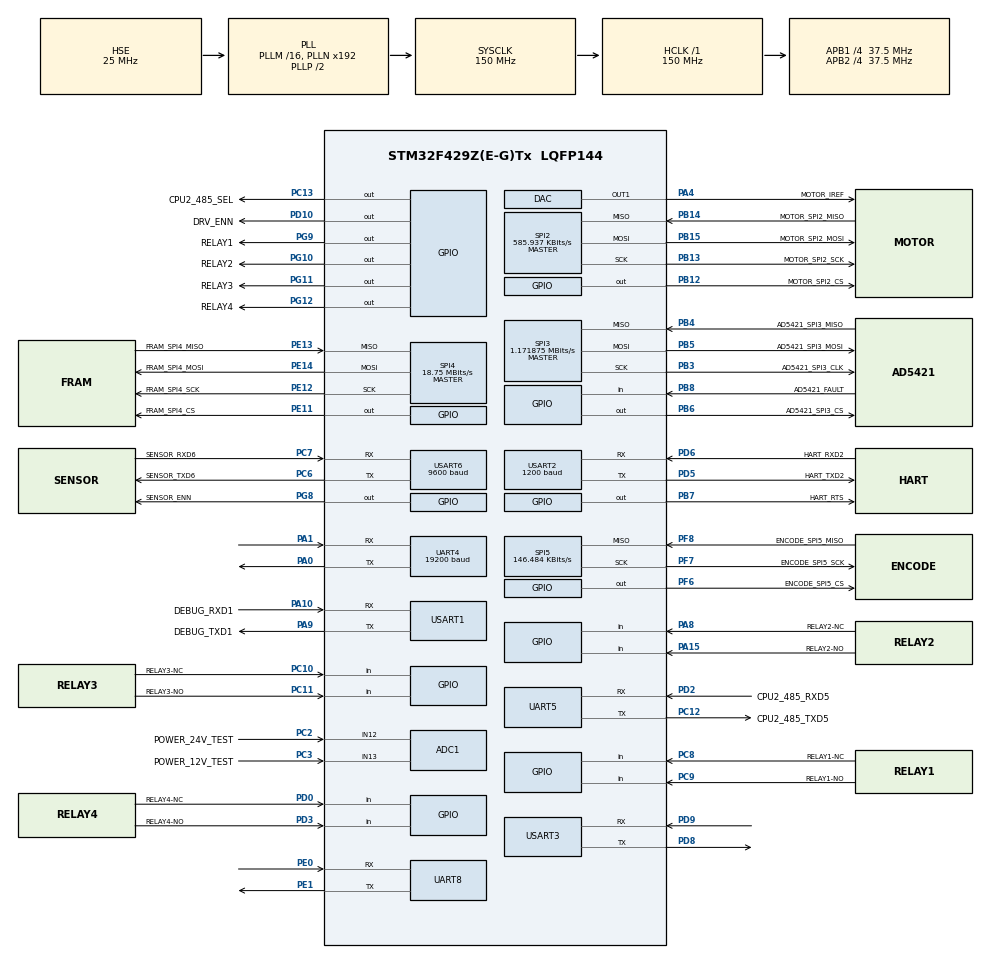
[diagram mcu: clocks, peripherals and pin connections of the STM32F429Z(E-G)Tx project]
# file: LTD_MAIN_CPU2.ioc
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ADC1.Channel-0\#ChannelRegularConversion=ADC_CHANNEL_12
ADC1.ClockPrescaler=ADC_CLOCK_SYNC_PCLK_DIV4
ADC1.ContinuousConvMode=ENABLE
ADC1.DMAContinuousRequests=ENABLE
ADC1.NbrOfConversionFlag=1
ADC1.Rank-0\#ChannelRegularConversion=1
ADC1.SamplingTime-0\#ChannelRegularConversion=ADC_SAMPLETIME_144CYCLES
ADC1.master=1
Dma.Request0=UART4_RX
Dma.Request1=SPI5_RX
Dma.Request2=USART1_RX
Dma.Request3=USART2_RX
Dma.Request4=UART5_RX
Dma.Request5=UART5_TX
Dma.Request6=USART2_TX
Dma.Request7=USART6_TX
Dma.Request8=USART6_RX
Dma.Request9=ADC1
Dma.ADC1.9.Direction=DMA_PERIPH_TO_MEMORY
Dma.ADC1.9.FIFOMode=DMA_FIFOMODE_DISABLE
Dma.ADC1.9.Instance=DMA2_Stream0
Dma.ADC1.9.MemDataAlignment=DMA_MDATAALIGN_WORD
Dma.ADC1.9.MemInc=DMA_MINC_DISABLE
Dma.ADC1.9.Mode=DMA_CIRCULAR
Dma.ADC1.9.PeriphDataAlignment=DMA_PDATAALIGN_WORD
Dma.ADC1.9.PeriphInc=DMA_PINC_DISABLE
Dma.ADC1.9.Priority=DMA_PRIORITY_LOW
Dma.SPI5_RX.1.Direction=DMA_PERIPH_TO_MEMORY
Dma.SPI5_RX.1.FIFOMode=DMA_FIFOMODE_DISABLE
Dma.SPI5_RX.1.Instance=DMA2_Stream3
Dma.SPI5_RX.1.MemDataAlignment=DMA_MDATAALIGN_BYTE
Dma.SPI5_RX.1.MemInc=DMA_MINC_ENABLE
Dma.SPI5_RX.1.Mode=DMA_NORMAL
Dma.SPI5_RX.1.PeriphDataAlignment=DMA_PDATAALIGN_BYTE
Dma.SPI5_RX.1.PeriphInc=DMA_PINC_DISABLE
Dma.SPI5_RX.1.Priority=DMA_PRIORITY_LOW
Dma.UART4_RX.0.Direction=DMA_PERIPH_TO_MEMORY
Dma.UART4_RX.0.FIFOMode=DMA_FIFOMODE_DISABLE
Dma.UART4_RX.0.Instance=DMA1_Stream2
Dma.UART4_RX.0.MemDataAlignment=DMA_MDATAALIGN_BYTE
Dma.UART4_RX.0.MemInc=DMA_MINC_ENABLE
Dma.UART4_RX.0.Mode=DMA_NORMAL
Dma.UART4_RX.0.PeriphDataAlignment=DMA_PDATAALIGN_BYTE
Dma.UART4_RX.0.PeriphInc=DMA_PINC_DISABLE
Dma.UART4_RX.0.Priority=DMA_PRIORITY_LOW
Dma.UART5_RX.4.Direction=DMA_PERIPH_TO_MEMORY
Dma.UART5_RX.4.FIFOMode=DMA_FIFOMODE_DISABLE
Dma.UART5_RX.4.Instance=DMA1_Stream0
Dma.UART5_RX.4.MemDataAlignment=DMA_MDATAALIGN_BYTE
Dma.UART5_RX.4.MemInc=DMA_MINC_ENABLE
Dma.UART5_RX.4.Mode=DMA_NORMAL
Dma.UART5_RX.4.PeriphDataAlignment=DMA_PDATAALIGN_BYTE
Dma.UART5_RX.4.PeriphInc=DMA_PINC_DISABLE
Dma.UART5_RX.4.Priority=DMA_PRIORITY_LOW
Dma.UART5_TX.5.Direction=DMA_MEMORY_TO_PERIPH
Dma.UART5_TX.5.FIFOMode=DMA_FIFOMODE_DISABLE
Dma.UART5_TX.5.Instance=DMA1_Stream7
Dma.UART5_TX.5.MemDataAlignment=DMA_MDATAALIGN_BYTE
Dma.UART5_TX.5.MemInc=DMA_MINC_ENABLE
Dma.UART5_TX.5.Mode=DMA_NORMAL
Dma.UART5_TX.5.PeriphDataAlignment=DMA_PDATAALIGN_BYTE
Dma.UART5_TX.5.PeriphInc=DMA_PINC_DISABLE
Dma.UART5_TX.5.Priority=DMA_PRIORITY_LOW
Dma.USART1_RX.2.Direction=DMA_PERIPH_TO_MEMORY
Dma.USART1_RX.2.FIFOMode=DMA_FIFOMODE_DISABLE
Dma.USART1_RX.2.Instance=DMA2_Stream2
Dma.USART1_RX.2.MemDataAlignment=DMA_MDATAALIGN_BYTE
Dma.USART1_RX.2.MemInc=DMA_MINC_ENABLE
Dma.USART1_RX.2.Mode=DMA_NORMAL
Dma.USART1_RX.2.PeriphDataAlignment=DMA_PDATAALIGN_BYTE
Dma.USART1_RX.2.PeriphInc=DMA_PINC_DISABLE
Dma.USART1_RX.2.Priority=DMA_PRIORITY_LOW
Dma.USART2_RX.3.Direction=DMA_PERIPH_TO_MEMORY
Dma.USART2_RX.3.FIFOMode=DMA_FIFOMODE_DISABLE
Dma.USART2_RX.3.Instance=DMA1_Stream5
Dma.USART2_RX.3.MemDataAlignment=DMA_MDATAALIGN_BYTE
Dma.USART2_RX.3.MemInc=DMA_MINC_ENABLE
Dma.USART2_RX.3.Mode=DMA_NORMAL
Dma.USART2_RX.3.PeriphDataAlignment=DMA_PDATAALIGN_BYTE
Dma.USART2_RX.3.PeriphInc=DMA_PINC_DISABLE
Dma.USART2_RX.3.Priority=DMA_PRIORITY_LOW
Dma.USART2_TX.6.Direction=DMA_MEMORY_TO_PERIPH
Dma.USART2_TX.6.FIFOMode=DMA_FIFOMODE_DISABLE
Dma.USART2_TX.6.Instance=DMA1_Stream6
Dma.USART2_TX.6.MemDataAlignment=DMA_MDATAALIGN_BYTE
Dma.USART2_TX.6.MemInc=DMA_MINC_ENABLE
Dma.USART2_TX.6.Mode=DMA_NORMAL
Dma.USART2_TX.6.PeriphDataAlignment=DMA_PDATAALIGN_BYTE
Dma.USART2_TX.6.PeriphInc=DMA_PINC_DISABLE
Dma.USART2_TX.6.Priority=DMA_PRIORITY_LOW
Dma.USART6_RX.8.Direction=DMA_PERIPH_TO_MEMORY
Dma.USART6_RX.8.FIFOMode=DMA_FIFOMODE_DISABLE
Dma.USART6_RX.8.Instance=DMA2_Stream1
Dma.USART6_RX.8.MemDataAlignment=DMA_MDATAALIGN_BYTE
Dma.USART6_RX.8.MemInc=DMA_MINC_ENABLE
Dma.USART6_RX.8.Mode=DMA_NORMAL
Dma.USART6_RX.8.PeriphDataAlignment=DMA_PDATAALIGN_BYTE
Dma.USART6_RX.8.PeriphInc=DMA_PINC_DISABLE
Dma.USART6_RX.8.Priority=DMA_PRIORITY_LOW
Dma.USART6_TX.7.Direction=DMA_MEMORY_TO_PERIPH
Dma.USART6_TX.7.FIFOMode=DMA_FIFOMODE_DISABLE
Dma.USART6_TX.7.Instance=DMA2_Stream6
Dma.USART6_TX.7.MemDataAlignment=DMA_MDATAALIGN_BYTE
Dma.USART6_TX.7.MemInc=DMA_MINC_ENABLE
Dma.USART6_TX.7.Mode=DMA_NORMAL
Dma.USART6_TX.7.PeriphDataAlignment=DMA_PDATAALIGN_BYTE
Dma.USART6_TX.7.PeriphInc=DMA_PINC_DISABLE
Dma.USART6_TX.7.Priority=DMA_PRIORITY_LOW
IWDG.Prescaler=IWDG_PRESCALER_32
Mcu.Family=STM32F4
Mcu.Name=STM32F429Z(E-G)Tx
Mcu.Package=LQFP144
NVIC.ADC_IRQn=true\:1\:0\:false\:false\:true\:true\:true\:true
NVIC.DMA1_Stream0_IRQn=true\:2\:0\:false\:false\:true\:false\:true\:true
NVIC.DMA1_Stream2_IRQn=true\:3\:0\:false\:false\:true\:false\:true\:true
NVIC.DMA1_Stream5_IRQn=true\:4\:0\:false\:false\:true\:false\:true\:true
NVIC.DMA1_Stream6_IRQn=true\:4\:0\:false\:false\:true\:false\:true\:true
NVIC.DMA1_Stream7_IRQn=true\:2\:0\:false\:false\:true\:false\:true\:true
NVIC.DMA2_Stream1_IRQn=true\:1\:0\:false\:false\:true\:false\:true\:true
NVIC.DMA2_Stream2_IRQn=true\:4\:0\:false\:false\:true\:false\:true\:true
NVIC.DMA2_Stream3_IRQn=true\:0\:0\:false\:false\:true\:false\:true\:true
NVIC.DMA2_Stream6_IRQn=true\:1\:0\:false\:false\:true\:false\:true\:true
NVIC.PriorityGroup=NVIC_PRIORITYGROUP_4
NVIC.TIM1_UP_TIM10_IRQn=true\:0\:0\:true\:false\:true\:true\:true\:true
NVIC.TIM4_IRQn=true\:3\:0\:false\:false\:true\:true\:true\:true
NVIC.UART4_IRQn=true\:2\:0\:true\:false\:true\:true\:true\:true
NVIC.UART5_IRQn=true\:2\:0\:true\:false\:true\:true\:true\:true
NVIC.USART1_IRQn=true\:4\:0\:false\:false\:true\:true\:true\:true
NVIC.USART2_IRQn=true\:4\:0\:false\:false\:true\:true\:true\:true
NVIC.USART6_IRQn=true\:1\:0\:false\:false\:true\:true\:true\:true
PA0/WKUP.Mode=Asynchronous
PA0/WKUP.Signal=UART4_TX
PA1.Mode=Asynchronous
PA1.Signal=UART4_RX
PA10.GPIO_Label=DEBUG_RXD1
PA10.GPIO_PuPd=GPIO_PULLUP
PA10.Mode=Asynchronous
PA10.Signal=USART1_RX
PA13.Mode=Serial_Wire
PA13.Signal=SYS_JTMS-SWDIO
PA14.Mode=Serial_Wire
PA14.Signal=SYS_JTCK-SWCLK
PA15.GPIO_Label=RELAY2-NO
PA15.Signal=GPIO_Input
PA4.GPIO_Label=MOTOR_IREF
PA4.Signal=COMP_DAC1_group
PA8.GPIO_Label=RELAY2-NC
PA8.Signal=GPIO_Input
PA9.GPIO_Label=DEBUG_TXD1
PA9.Mode=Asynchronous
PA9.Signal=USART1_TX
PB12.GPIO_Label=MOTOR_SPI2_CS
PB12.PinState=GPIO_PIN_SET
PB12.Signal=GPIO_Output
PB13.GPIO_Label=MOTOR_SPI2_SCK
PB13.Mode=Full_Duplex_Master
PB13.Signal=SPI2_SCK
PB14.GPIO_Label=MOTOR_SPI2_MISO
PB14.Mode=Full_Duplex_Master
PB14.Signal=SPI2_MISO
PB15.GPIO_Label=MOTOR_SPI2_MOSI
PB15.Mode=Full_Duplex_Master
PB15.Signal=SPI2_MOSI
PB3.GPIO_Label=AD5421_SPI3_CLK
PB3.Mode=Full_Duplex_Master
PB3.Signal=SPI3_SCK
PB4.GPIO_Label=AD5421_SPI3_MISO
PB4.Mode=Full_Duplex_Master
PB4.Signal=SPI3_MISO
PB5.GPIO_Label=AD5421_SPI3_MOSI
PB5.Mode=Full_Duplex_Master
PB5.Signal=SPI3_MOSI
PB6.GPIO_Label=AD5421_SPI3_CS
PB6.Signal=GPIO_Output
PB7.GPIO_Label=HART_RTS
PB7.Signal=GPIO_Output
PB8.GPIO_Label=AD5421_FAULT
PB8.Signal=GPIO_Input
PC10.GPIO_Label=RELAY3-NC
PC10.Signal=GPIO_Input
PC11.GPIO_Label=RELAY3-NO
PC11.Signal=GPIO_Input
PC12.GPIO_Label=CPU2_485_TXD5
PC12.Mode=Asynchronous
PC12.Signal=UART5_TX
PC13.GPIO_Label=CPU2_485_SEL
PC13.PinState=GPIO_PIN_SET
PC13.Signal=GPIO_Output
PC2.GPIO_Label=POWER_24V_TEST
PC2.Signal=ADCx_IN12
PC3.GPIO_Label=POWER_12V_TEST
PC3.Signal=ADCx_IN13
PC6.GPIO_Label=SENSOR_TXD6
PC6.Mode=Asynchronous
PC6.Signal=USART6_TX
PC7.GPIO_Label=SENSOR_RXD6
PC7.Mode=Asynchronous
PC7.Signal=USART6_RX
PC8.GPIO_Label=RELAY1-NC
PC8.Signal=GPIO_Input
PC9.GPIO_Label=RELAY1-NO
PC9.Signal=GPIO_Input
PD0.GPIO_Label=RELAY4-NC
PD0.Signal=GPIO_Input
PD10.GPIO_Label=DRV_ENN
PD10.PinState=GPIO_PIN_SET
PD10.Signal=GPIO_Output
PD2.GPIO_Label=CPU2_485_RXD5
PD2.Mode=Asynchronous
PD2.Signal=UART5_RX
PD3.GPIO_Label=RELAY4-NO
PD3.Signal=GPIO_Input
PD5.GPIO_Label=HART_TXD2
PD5.Mode=Asynchronous
PD5.Signal=USART2_TX
PD6.GPIO_Label=HART_RXD2
PD6.Mode=Asynchronous
PD6.Signal=USART2_RX
PD8.Mode=Asynchronous
PD8.Signal=USART3_TX
PD9.Mode=Asynchronous
PD9.Signal=USART3_RX
PE0.Mode=Asynchronous
PE0.Signal=UART8_RX
PE1.Mode=Asynchronous
PE1.Signal=UART8_TX
PE11.GPIO_Label=FRAM_SPI4_CS
PE11.PinState=GPIO_PIN_SET
PE11.Signal=GPIO_Output
PE12.GPIO_Label=FRAM_SPI4_SCK
PE12.Mode=Full_Duplex_Master
PE12.Signal=SPI4_SCK
PE13.GPIO_Label=FRAM_SPI4_MISO
PE13.Mode=Full_Duplex_Master
PE13.Signal=SPI4_MISO
PE14.GPIO_Label=FRAM_SPI4_MOSI
PE14.Mode=Full_Duplex_Master
PE14.Signal=SPI4_MOSI
PF6.GPIO_Label=ENCODE_SPI5_CS
PF6.PinState=GPIO_PIN_SET
PF6.Signal=GPIO_Output
PF7.GPIO_Label=ENCODE_SPI5_SCK
PF7.Mode=RX_Only_Simplex_Unidirect_Master
PF7.Signal=SPI5_SCK
PF8.GPIO_Label=ENCODE_SPI5_MISO
PF8.GPIO_PuPd=GPIO_PULLDOWN
PF8.Mode=RX_Only_Simplex_Unidirect_Master
PF8.Signal=SPI5_MISO
PG10.GPIO_Label=RELAY2
PG10.Signal=GPIO_Output
PG11.GPIO_Label=RELAY3
PG11.Signal=GPIO_Output
PG12.GPIO_Label=RELAY4
PG12.Signal=GPIO_Output
PG8.GPIO_Label=SENSOR_ENN
PG8.PinState=GPIO_PIN_SET
PG8.Signal=GPIO_Output
PG9.GPIO_Label=RELAY1
PG9.Signal=GPIO_Output
PH0/OSC_IN.Mode=HSE-External-Oscillator
PH0/OSC_IN.Signal=RCC_OSC_IN
PH1/OSC_OUT.Mode=HSE-External-Oscillator
PH1/OSC_OUT.Signal=RCC_OSC_OUT
ProjectManager.HeapSize=0x200
ProjectManager.StackSize=0x400
ProjectManager.TargetToolchain=STM32CubeIDE
RCC.48MHZClocksFreq_Value=75000000
RCC.AHBFreq_Value=150000000
RCC.APB1CLKDivider=RCC_HCLK_DIV4
RCC.APB1Freq_Value=37500000
RCC.APB1TimFreq_Value=75000000
RCC.APB2CLKDivider=RCC_HCLK_DIV4
RCC.APB2Freq_Value=37500000
RCC.APB2TimFreq_Value=75000000
RCC.CortexFreq_Value=150000000
RCC.HCLKFreq_Value=150000000
RCC.HSE_VALUE=25000000
RCC.HSI_VALUE=16000000
RCC.LSE_VALUE=32768
RCC.PLLSourceVirtual=RCC_PLLSOURCE_HSE
RCC.SYSCLKFreq_VALUE=150000000
RCC.SYSCLKSource=RCC_SYSCLKSOURCE_PLLCLK
RCC.VCOOutputFreq_Value=300000000
SH.ADCx_IN12.0=ADC1_IN12,IN12
SH.ADCx_IN13.0=ADC1_IN13,IN13
SH.COMP_DAC1_group.0=DAC_OUT1,DAC_OUT1
SPI2.BaudRatePrescaler=SPI_BAUDRATEPRESCALER_64
SPI2.CLKPhase=SPI_PHASE_2EDGE
SPI2.CLKPolarity=SPI_POLARITY_HIGH
SPI2.CalculateBaudRate=585.937 KBits/s
SPI2.Direction=SPI_DIRECTION_2LINES
SPI2.Mode=SPI_MODE_MASTER
SPI2.VirtualType=VM_MASTER
SPI3.BaudRatePrescaler=SPI_BAUDRATEPRESCALER_32
SPI3.CLKPhase=SPI_PHASE_2EDGE
SPI3.CalculateBaudRate=1.171875 MBits/s
SPI3.Direction=SPI_DIRECTION_2LINES
SPI3.Mode=SPI_MODE_MASTER
SPI3.VirtualType=VM_MASTER
SPI4.BaudRatePrescaler=SPI_BAUDRATEPRESCALER_2
SPI4.CalculateBaudRate=18.75 MBits/s
SPI4.Direction=SPI_DIRECTION_2LINES
SPI4.Mode=SPI_MODE_MASTER
SPI4.VirtualType=VM_MASTER
SPI5.BaudRatePrescaler=SPI_BAUDRATEPRESCALER_256
SPI5.CLKPhase=SPI_PHASE_2EDGE
SPI5.CLKPolarity=SPI_POLARITY_HIGH
SPI5.CalculateBaudRate=146.484 KBits/s
SPI5.Direction=SPI_DIRECTION_2LINES_RXONLY
SPI5.Mode=SPI_MODE_MASTER
SPI5.VirtualType=VM_MASTER
TIM1.Period=99
TIM1.Prescaler=7499
TIM4.AutoReloadPreload=TIM_AUTORELOAD_PRELOAD_ENABLE
TIM4.Period=1249
TIM4.Prescaler=14999
UART4.BaudRate=19200
UART4.VirtualMode=Asynchronous
UART5.VirtualMode=Asynchronous
UART8.VirtualMode=Asynchronous
USART1.VirtualMode=VM_ASYNC
USART2.BaudRate=1200
USART2.Parity=PARITY_NONE
USART2.VirtualMode=VM_ASYNC
USART2.WordLength=WORDLENGTH_9B
USART3.VirtualMode=VM_ASYNC
USART6.BaudRate=9600
USART6.VirtualMode=VM_ASYNC
VP_CRC_VS_CRC.Mode=CRC_Activate
VP_IWDG_VS_IWDG.Mode=IWDG_Activate
VP_TIM1_VS_ClockSourceINT.Mode=Internal
VP_TIM4_VS_ClockSourceINT.Mode=Internal
board=custom

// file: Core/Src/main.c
/* USER CODE BEGIN Header */
/**
 ******************************************************************************
 * @file           : main.c
 * @brief          : Main program body
 ******************************************************************************
 * @attention
 *
 * Copyright (c) 2025 STMicroelectronics.
 * All rights reserved.
 *
 * This software is licensed under terms that can be found in the LICENSE file
 * in the root directory of this software component.
 * If no LICENSE file comes with this software, it is provided AS-IS.
 *
 ******************************************************************************
 */
/* USER CODE END Header */
#include "main.h"
#include "adc.h"
#include "crc.h"
#include "dac.h"
#include "dma.h"
#include "iwdg.h"
#include "spi.h"
#include "tim.h"
#include "usart.h"
#include "gpio.h"

/* USER CODE BEGIN Includes */
#include "app_main.h"
#include "motor_ctrl.h"
/* USER CODE END Includes */

void SystemClock_Config(void);

int main(void)
{

  /* MCU Configuration--------------------------------------------------------*/

  /* Reset of all peripherals, Initializes the Flash interface and the Systick. */
  HAL_Init();

  /* Configure the system clock */
  SystemClock_Config();

  /* Initialize all configured peripherals */
  MX_GPIO_Init();
  MX_DMA_Init();
  MX_ADC1_Init();
  MX_DAC_Init();
  MX_UART4_Init();
  MX_UART5_Init();
  MX_UART8_Init();
  MX_USART1_UART_Init();
  MX_USART6_UART_Init();
  MX_SPI3_Init();
  MX_SPI2_Init();
  MX_SPI4_Init();
  MX_SPI5_Init();
  MX_USART2_UART_Init();
  MX_USART3_UART_Init();
  MX_TIM1_Init();
  MX_CRC_Init();
  MX_IWDG_Init();
  MX_TIM4_Init();
  /* USER CODE BEGIN 2 */
	/* 业务初始化前先清 TMC5130 残留运动状态，避免运动中复位后继续跑。 */
	(void)MotorCtrl_BootSafeStop();
	App_Init();
  /* USER CODE END 2 */

  /* Infinite loop */
	while (1) {

    /* USER CODE BEGIN 3 */
		App_MainLoop();
	}
  /* USER CODE END 3 */
}

void SystemClock_Config(void)
{
  RCC_OscInitTypeDef RCC_OscInitStruct = {0};
  RCC_ClkInitTypeDef RCC_ClkInitStruct = {0};

  /** Configure the main internal regulator output voltage
  */
  __HAL_RCC_PWR_CLK_ENABLE();
  __HAL_PWR_VOLTAGESCALING_CONFIG(PWR_REGULATOR_VOLTAGE_SCALE1);

  /** Initializes the RCC Oscillators according to the specified parameters
  * in the RCC_OscInitTypeDef structure.
  */
  RCC_OscInitStruct.OscillatorType = RCC_OSCILLATORTYPE_LSI|RCC_OSCILLATORTYPE_HSE;
  RCC_OscInitStruct.HSEState = RCC_HSE_ON;
  RCC_OscInitStruct.LSIState = RCC_LSI_ON;
  RCC_OscInitStruct.PLL.PLLState = RCC_PLL_ON;
  RCC_OscInitStruct.PLL.PLLSource = RCC_PLLSOURCE_HSE;
  RCC_OscInitStruct.PLL.PLLM = 16;
  RCC_OscInitStruct.PLL.PLLN = 192;
  RCC_OscInitStruct.PLL.PLLP = RCC_PLLP_DIV2;
  RCC_OscInitStruct.PLL.PLLQ = 4;
  if (HAL_RCC_OscConfig(&RCC_OscInitStruct) != HAL_OK)
  {
    Error_Handler();
  }

  /** Initializes the CPU, AHB and APB buses clocks
  */
  RCC_ClkInitStruct.ClockType = RCC_CLOCKTYPE_HCLK|RCC_CLOCKTYPE_SYSCLK
                              |RCC_CLOCKTYPE_PCLK1|RCC_CLOCKTYPE_PCLK2;
  RCC_ClkInitStruct.SYSCLKSource = RCC_SYSCLKSOURCE_PLLCLK;
  RCC_ClkInitStruct.AHBCLKDivider = RCC_SYSCLK_DIV1;
  RCC_ClkInitStruct.APB1CLKDivider = RCC_HCLK_DIV4;
  RCC_ClkInitStruct.APB2CLKDivider = RCC_HCLK_DIV4;

  if (HAL_RCC_ClockConfig(&RCC_ClkInitStruct, FLASH_LATENCY_4) != HAL_OK)
  {
    Error_Handler();
  }
}

void Error_Handler(void)
{
	__disable_irq();
	while (1) {
	}
}
